# SSE320 register map
Vendor: ARM Ltd.; Series: ARMv8.1-M Mainline; File version: 1.0
CPU: CM85 r0p0, little endian, MPU, FPU, 3 interrupt priority bits, 8 SAU regions
Registers are 32-bit, read-write, reset 0x0 unless marked. A register's access mark holds for its fields unless they carry their own. Offsets are from the block's base; [hi:lo] are bit positions; {n}, {i} and the like mark numbered series; 'fields as' and 'values as' point back to an identical list.

## AudioI2S
Base 0x48201000
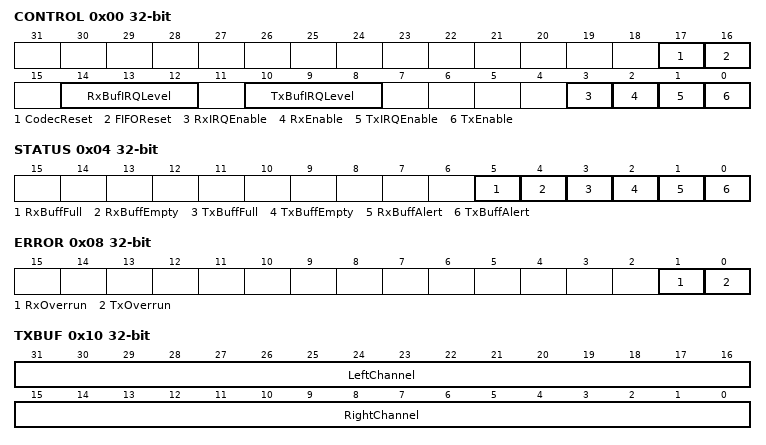
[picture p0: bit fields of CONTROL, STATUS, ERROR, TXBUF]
0x00 CONTROL
  [17] CodecReset — Audio codec reset control
  [16] FIFOReset
  [14:12] RxBufIRQLevel — Receive Buffer IRQ Water level
  [10:8] TxBufIRQLevel — Transmit Buffer IRQ Water level
  [3] RxIRQEnable — Enable Interrupt on Receive Buffer
  [2] RxEnable — Enable Receive Buffer
  [1] TxIRQEnable — Enable Interrupt on Transmit Buffer
  [0] TxEnable — Enable Transfer Buffer
0x04 STATUS ro
  [5] RxBuffFull — Receive Buffer Full
  [4] RxBuffEmpty — Receive Buffer Empty
  [3] TxBuffFull — Transmit Buffer Full
  [2] TxBuffEmpty — Transmit Buffer Empty
  [1] RxBuffAlert — Receive Buffer Alert (Depends on Water level)
  [0] TxBuffAlert — Transmit Buffer Alert (Depends on Water level)
0x08 ERROR — Error status register
  [1] RxOverrun — Receive buffer ovverrun. Set this bit to clear.
  [0] TxOverrun — Transmit buffer ovverrun or underrun. Set this bit to clear.
0x0C DIVIDE — Clock Divide Ratio register
  [9:0] LRDIV — Left/Right. The default value is 0x80
0x10 TXBUF wo — Transmit Buffer FIFO Data register
  [31:16] LeftChannel — Left channel value
  [15:0] RightChannel — Right channel value
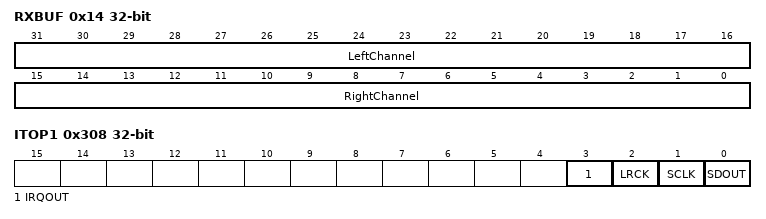
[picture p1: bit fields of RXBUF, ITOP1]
0x14 RXBUF ro — Receive Buffer FIFO Data register
  fields as TXBUF
0x300 ITCR — Integration Test Control register
  [0] ITCR — Integration test control bit
0x304 ITIP1 — Integration Test Input register 1
  [0] SDIN — SDIN pin value
0x308 ITOP1 — Integration Test Output register 1
  [3] IRQOUT — IRQOUT signal value
  [2] LRCK — LRCK signal value
  [1] SCLK — SLCK signal value
  [0] SDOUT — SDOUT signal value

## HDLCD — HDLCD (Non-Secure)
Base 0x40310000
Same registers: HDLCD_Secure 0x50310000
0x00 VERSION ro
0x10 RAW_INT_STAT — Raw Interrupt Status Register
0x14 INT_CLR wo — Interrupt Clear Register
0x18 INT_MASK — Interrupt Clear Register
0x1C INT_STAT — Interrupt Status Register
0x20 USER_OUTPUT
0x100 FB_BASE_ADDR — Frame Buffer Base Address Register
0x104 FB_LINE_LENGTH — Frame Buffer Line Length Register
0x108 FB_LINE_COUNT — Frame Buffer Line Count Register
0x10C FB_LINE_PITCH — Frame Buffer Line Pitch Register
0x110 BUS_OPTIONS
0x200 VSYNC_WIDTH — Vertical Synch Register
0x204 VSYNC_BACK_PORCH_WIDTH — Vertical Back Porch Width Register
0x208 VSYNC_DATA_WIDTH — Vertical Data Width Register
0x20C VSYNC_FRONT_PORCH_WIDTH — Vertical Front Porch Width Register
0x210 HSYNC_WIDTH — Horizontal Synch Register
0x214 HSYNC_BACK_PORCH_WIDTH — Horizontal Back Porch Width Register
0x218 HSYNC_DATA_WIDTH — Horizontal Data Width Register
0x21C HSYNC_FRONT_PORCH_WIDTH — Horizontal Front Porch Width Register
0x220 POLARITIES
0x230 COMMAND
0x240 PIXEL_FORMAT
0x244 RED_SELECT
0x248 GREEN_SELECT
0x24C BLUE_SELECT

## KMU — Key Management Unit (Secure)
Base 0x5009E000
0x00 KMUBC ro — KMU Build Configuration register.
0x04 KMUIS ro — KMU Interrupt Status register.
0x08 KMUIE — KMU Interrupt Enable register.
0x0C KMUIC — KMU Interrupt Clear register.
0x10 KMUPRBGSI — PRBG Seed Input register.
0x30 KMUKSC_n — KMU key slot configuration n register.
0xB0 KMUDKPA_n — KMU Destination Key Port Address n Register.
0x130 KMUKSC_0_n — Key slot word 0 of key slot [0].
{0x130+0x20*i} KMUKSK_{i}_m (i=1..6) — Key slot word {i} of key slot [{i}].
0x210 KMUKSK_7_m — Key slot words 7 of key slot [7].
0x530 KMURD_8 ro — When this register is read, it provides a random delay of 0-7 clocks.
0x534 KMURD_16 ro — When this register is read, it provides a random delay of 0-15 clocks.
0x538 KMURD_32 ro — When this register is read, it provides a random delay of 0-31 clocks.
0xFD0 PIDR4 ro reset 0x4 — The Peripheral ID4 register.
0xFE0 PIDR0 ro reset 0xF3 — The Peripheral ID0 register.
0xFE4 PIDR1 ro reset 0xB0 — The Peripheral ID1 register.
0xFE8 PIDR2 ro reset 0x1B — The Peripheral ID2 register.
0xFEC PIDR3 ro — The Peripheral ID3 register.
0xFF0 CIDR0 ro reset 0xD — The Component ID0 register.
0xFF4 CIDR1 ro reset 0xF0 — The Component ID1 register.
0xFF8 CIDR2 ro reset 0x5 — The Component ID2 register.
0xFFC CIDR3 ro reset 0xB1 — The Component ID3 register.
